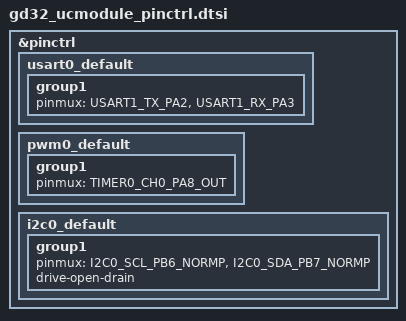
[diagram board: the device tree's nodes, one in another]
/*
 * Copyright (c) 2023, Electrolance Solutions
 * SPDX-License-Identifier: Apache-2.0
 */

#include <dt-bindings/pinctrl/gd32f303c(b-c-e-g)xx-pinctrl.h>

&pinctrl {
	usart0_default: usart0_default {
		group1 {
			pinmux = <USART1_TX_PA2>, <USART1_RX_PA3>;
		};
	};

	pwm0_default: pwm0_default {
		group1 {
			pinmux = <TIMER0_CH0_PA8_OUT>;
		};
	};

	i2c0_default: i2c0_default {
		group1 {
			pinmux = <I2C0_SCL_PB6_NORMP>, <I2C0_SDA_PB7_NORMP>;
			drive-open-drain;
		};
	};

};
